# UPD70F3508 register map
Vendor: Renesas; Series: V850E2/Px4; File version: 1.0
CPU: other r0p0, little endian, no MPU, FPU, 4 interrupt priority bits
Registers are 8-bit, read-write, reset 0x0 unless marked. A register's access mark holds for its fields unless they carry their own. Offsets are from the block's base; [hi:lo] are bit positions; {n}, {i} and the like mark numbered series.

## CSIH0_B0 — Queue-Equipped Three-Line Serial Interface H 0, Bank 0 (control/config registers at base0)
Base 0xFF6C0000
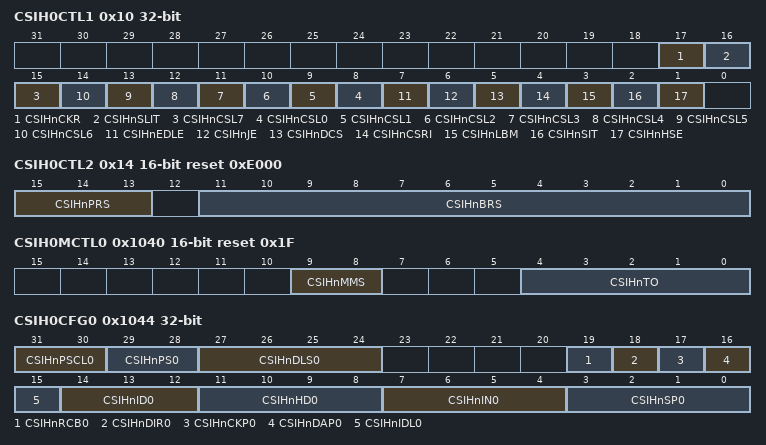
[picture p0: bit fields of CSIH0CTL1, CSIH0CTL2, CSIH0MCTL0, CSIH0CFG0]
0x10 CSIH0CTL1 32-bit — CSIHn Control Register 1 — clock phase, interrupt timing, chip-select levels, job/loop-back/handshake modes
  [17] CSIHnCKR — Clock phase of CSIHnTSCK (0=default high, 1=default low)
  [16] CSIHnSLIT — Interrupt timing select for CSIHnTIC
  [15] CSIHnCSL7 — Chip-select 7 active output level (0=active-low, 1=active-high)
  [n+8] CSIHnCSL{n} (n=0..6) — Chip-select {n} active output level
  [7] CSIHnEDLE — Extended data length mode enable
  [6] CSIHnJE — Job mode enable
  [5] CSIHnDCS — Data consistency check enable
  [4] CSIHnCSRI — Chip-select behavior after last transfer (0=hold active, 1=return inactive)
  [3] CSIHnLBM — Loop-back mode enable
  [2] CSIHnSIT — Interrupt delay mode (0=no delay, 1=half-clock delay)
  [1] CSIHnHSE — Handshake function enable
0x14 CSIH0CTL2 16-bit reset 0xE000 — CSIHn Control Register 2 — operating mode, prescaler, baud rate
  [15:13] CSIHnPRS — Prescaler select [2:0] (000=PCLK, 001=PCLK/2, ..., 111=slave ext clock)
  [11:0] CSIHnBRS — Baud rate select [11:0]
0x1040 CSIH0MCTL0 16-bit reset 0x1F — CSIHn Memory Control Register 0 — memory mode and time-out setting
  [9:8] CSIHnMMS — Memory mode select [1:0] (00=FIFO, 01=double-buffer, 10=Tx-only buffer)
  [4:0] CSIHnTO — Time-out setting [4:0] (00000=disabled, else n*8*BRG output clocks)
0x1044 CSIH0CFG0 32-bit — CSIHn Configuration Register 0 — chip-select 0 protocol settings
  [31:30] CSIHnPSCL0 — Prescaler select for CS0 [1:0]
  [29:28] CSIHnPS0 — Parity select for CS0 [1:0]
  [27:24] CSIHnDLS0 — Data length select for CS0 [3:0] (0000=16bit, 0001=1bit, ..., 1111=15bit)
  [19] CSIHnRCB0 — Recessive configuration for broadcasting CS0
  [18] CSIHnDIR0 — Data direction for CS0 (0=MSB first, 1=LSB first)
  [17] CSIHnCKP0 — Clock phase for CS0
  [16] CSIHnDAP0 — Data phase for CS0
  [15] CSIHnIDL0 — Idle enforcement config for CS0
  [14:12] CSIHnID0 — Idle time select for CS0 [2:0]
  [11:8] CSIHnHD0 — Hold time select for CS0 [3:0]
  [7:4] CSIHnIN0 — Inter-data delay time for CS0 [3:0]
  [3:0] CSIHnSP0 — Setup time for CS0 [3:0]
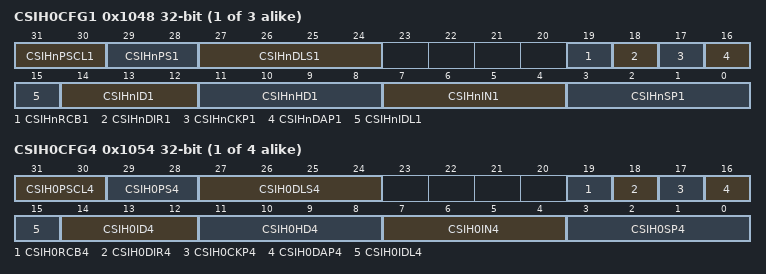
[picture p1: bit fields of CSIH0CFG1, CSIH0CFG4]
{0x1044+4i} CSIH0CFG{i} 32-bit (i=1..3) — CSIHn Configuration Register {i} — chip-select {i} protocol settings
  [31:30] CSIHnPSCL{i} — Prescaler select for CS{i} [1:0]
  [29:28] CSIHnPS{i} — Parity select for CS{i} [1:0]
  [27:24] CSIHnDLS{i} — Data length select for CS{i} [3:0]
  [19] CSIHnRCB{i} — Recessive config for CS{i}
  [18] CSIHnDIR{i} — Data direction for CS{i}
  [17] CSIHnCKP{i} — Clock phase for CS{i}
  [16] CSIHnDAP{i} — Data phase for CS{i}
  [15] CSIHnIDL{i} — Idle enforcement config for CS{i}
  [14:12] CSIHnID{i} — Idle time select for CS{i} [2:0]
  [11:8] CSIHnHD{i} — Hold time for CS{i} [3:0]
  [7:4] CSIHnIN{i} — Inter-data delay for CS{i} [3:0]
  [3:0] CSIHnSP{i} — Setup time for CS{i} [3:0]
{0x1044+4i} CSIH0CFG{i} 32-bit (i=4..7) — CSIH0 Configuration Register {i} — chip-select {i} protocol settings (CSIH0 only)
  [31:30] CSIH0PSCL{i} — Prescaler select for CS{i} [1:0]
  [29:28] CSIH0PS{i} — Parity select for CS{i} [1:0]
  [27:24] CSIH0DLS{i} — Data length select for CS{i} [3:0]
  [19] CSIH0RCB{i} — Recessive config for CS{i}
  [18] CSIH0DIR{i} — Data direction for CS{i}
  [17] CSIH0CKP{i} — Clock phase for CS{i}
  [16] CSIH0DAP{i} — Data phase for CS{i}
  [15] CSIH0IDL{i} — Idle enforcement config for CS{i}
  [14:12] CSIH0ID{i} — Idle time select for CS{i} [2:0]
  [11:8] CSIH0HD{i} — Hold time for CS{i} [3:0]
  [7:4] CSIH0IN{i} — Inter-data delay for CS{i} [3:0]
  [3:0] CSIH0SP{i} — Setup time for CS{i} [3:0]
